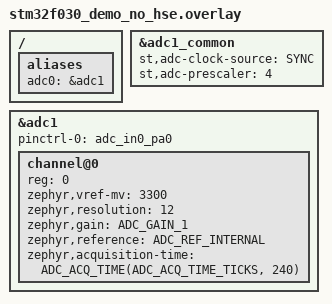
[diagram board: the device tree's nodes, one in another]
/*
 * Copyright (c) 2025 Hake Huang <hake.huang@gmail.com>.
 *
 * SPDX-License-Identifier: Apache-2.0
 */

/ {
	aliases {
		adc0 = &adc1;
	};
};

/* The board supplies the 48 MHz SYSCLK; the ADC common block only needs the
 * kernel clock source and prescaler.
 */
&adc1_common {
	st,adc-clock-source = "SYNC";
	st,adc-prescaler = <4>;
	status = "okay";
};

&adc1 {
	#io-channel-cells = <1>;
	#address-cells = <1>;
	#size-cells = <0>;
	pinctrl-0 = <&adc_in0_pa0>;
	pinctrl-names = "default";
	status = "okay";

	channel@0 {
		reg = <0>;
		zephyr,vref-mv = <3300>;
		zephyr,resolution = <12>;
		zephyr,gain = "ADC_GAIN_1";
		zephyr,reference = "ADC_REF_INTERNAL";
		zephyr,acquisition-time = <ADC_ACQ_TIME(ADC_ACQ_TIME_TICKS, 240)>;
	};
};
